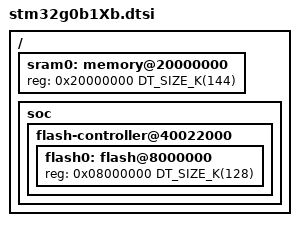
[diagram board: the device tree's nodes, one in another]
/*
 * Copyright (c) 2020 Thomas Stranger
 *
 * SPDX-License-Identifier: Apache-2.0
 */

#include <mem.h>
#include <st/g0/stm32g0b1.dtsi>

/ {
	sram0: memory@20000000 {
		reg = <0x20000000 DT_SIZE_K(144)>;
	};

	soc {
		flash-controller@40022000 {
			flash0: flash@8000000 {
				reg = <0x08000000 DT_SIZE_K(128)>;
			};
		};
	};
};
